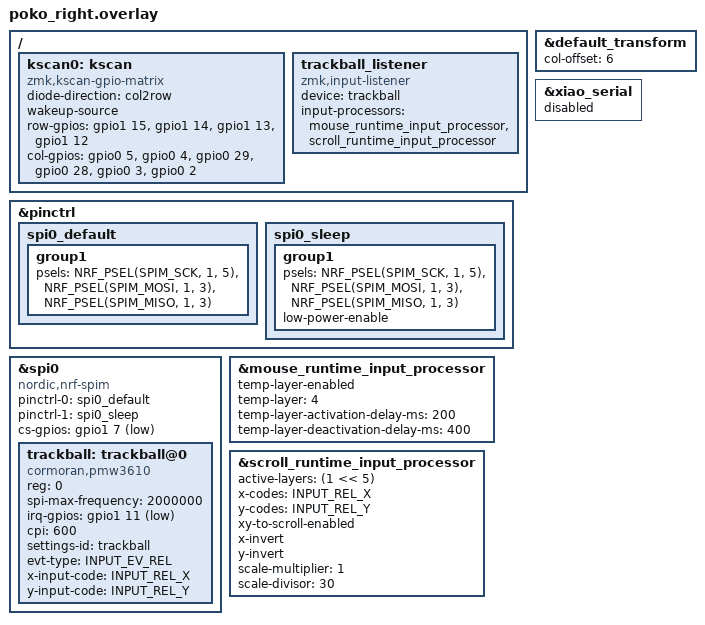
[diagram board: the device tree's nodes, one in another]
/*
 * poko 右手（セントラル・トラックボールあり）
 *
 * 右がセントラルなので zmk,input-split によるペリフェラル→セントラル転送は不要。
 * SPI + PMW3610 + input-listener をそのまま書く（実装ノート §7）。
 *
 * kscan は poko.dtsi の include より前に置く（poko.dtsi の chosen が &kscan0 を参照するため）。
 */

#include <zephyr/dt-bindings/gpio/gpio.h>

/ {
    /*
     * マトリクス 4行 × 6列（トラボ穴のぶん23キー）
     *
     * ⚠ いまは【試作基板】のピン割当（v0.1-proto と同一・左右共通）。
     *   本番基板 right.kicad_pcb の割当は下のコメントアウト側。戻すときは
     *   ピン番号だけでなく diode-direction と GPIO フラグも必ずセットで戻すこと。
     *
     * ダイオード向きは左と同じ。試作 = row2col / 本番 = col2row。
     * 欠番の SW19 = ROW3/COL0 → col-offset=6 で RC(3,6) ＝ トラックボール位置。
     */
    kscan0: kscan {
        compatible = "zmk,kscan-gpio-matrix";
        diode-direction = "col2row";
        wakeup-source;

        row-gpios
            = <&gpio1 15 (GPIO_ACTIVE_HIGH | GPIO_PULL_DOWN)>   // ROW0 = D10 / P1.15
            , <&gpio1 14 (GPIO_ACTIVE_HIGH | GPIO_PULL_DOWN)>   // ROW1 = D9  / P1.14
            , <&gpio1 13 (GPIO_ACTIVE_HIGH | GPIO_PULL_DOWN)>   // ROW2 = D8  / P1.13
            , <&gpio1 12 (GPIO_ACTIVE_HIGH | GPIO_PULL_DOWN)>   // ROW3 = D7  / P1.12
            ;
        col-gpios
            = <&gpio0  5 GPIO_ACTIVE_HIGH>   // COL0 = D5  / P0.05
            , <&gpio0  4 GPIO_ACTIVE_HIGH>   // COL1 = D4  / P0.04
            , <&gpio0 29 GPIO_ACTIVE_HIGH>   // COL2 = D3  / P0.29
            , <&gpio0 28 GPIO_ACTIVE_HIGH>   // COL3 = D2  / P0.28
            , <&gpio0  3 GPIO_ACTIVE_HIGH>   // COL4 = D1  / P0.03
            , <&gpio0  2 GPIO_ACTIVE_HIGH>   // COL5 = D0  / P0.02
            ;
    };
};

#include "poko.dtsi"
#include <input/processors.dtsi>
#include <input/processors/runtime-input-processor.dtsi>
#include <zephyr/dt-bindings/input/input-event-codes.h>

/* 右手の物理列0-5 を論理列6-11 へ */
&default_transform {
    col-offset = <6>;
};

/*
 * 3線 SPI: PMW3610 の SDIO は双方向1本なので MOSI/MISO を同じピンに割り当てる。
 *
 * ⚠ nRF52840 は SPIM0 と TWIM0 が周辺 ID を共有する。Zephyr の base xiao_ble.dts で
 *   &i2c0 が有効だとビルドが落ちるので、その場合は &spi0 → &spi3 に置換
 *   （SPIM3 は TWI と共有しない。pinctrl はどのピンにもルーティング可）。
 *
 * ⚠ いまは【試作基板】の配線:
 *     SCLK = P1.03 / SDIO = P1.05 / nCS = P1.07 / MOTION = P0.15
 *   本番基板 right.kicad_pcb は SCLK と SDIO が逆、MOTION も P1.11 (D6) に移動
 *   （コメントアウト側）。
 */
&pinctrl {
    spi0_default: spi0_default {
        group1 {
            psels = <NRF_PSEL(SPIM_SCK,  1, 5)>,   // SCLK = P1.05
                    <NRF_PSEL(SPIM_MOSI, 1, 3)>,   // SDIO = P1.03
                    <NRF_PSEL(SPIM_MISO, 1, 3)>;   //  〃   （同一ピン）
        };
    };

    spi0_sleep: spi0_sleep {
        group1 {
            psels = <NRF_PSEL(SPIM_SCK,  1, 5)>,
                    <NRF_PSEL(SPIM_MOSI, 1, 3)>,
                    <NRF_PSEL(SPIM_MISO, 1, 3)>;
            low-power-enable;
        };
    };
};

&spi0 {
    status = "okay";
    compatible = "nordic,nrf-spim";
    pinctrl-0 = <&spi0_default>;
    pinctrl-1 = <&spi0_sleep>;
    pinctrl-names = "default", "sleep";
    cs-gpios = <&gpio1 7 GPIO_ACTIVE_LOW>;   // nCS = P1.07

    trackball: trackball@0 {
        status = "okay";
        /* DYA Studio の Trackball タブ対応ドライバ（cormoran/zmk-driver-pmw3610-with-custom-studio-rpc）。
           west.yml・poko_right.conf と3点セット。 */
        compatible = "cormoran,pmw3610";
        reg = <0>;
        spi-max-frequency = <2000000>;   /* PMW3610 は 2MHz 上限 */

        /* MOTION = P1.11 (D6)。NRESET は R12(10k) で 3V3 プルアップ固定なので GPIO 不要 */
        irq-gpios = <&gpio1 11 (GPIO_ACTIVE_LOW | GPIO_PULL_UP)>;

        /* 初期値。DYA Studio から変更すると settings 側の値が優先される */
        cpi = <600>;   /* RMK 版 (keyboard.toml の cpi / POINTING_CPI) に揃える */

        /* DYA Studio 上の設定キー名（cpi@trackball など） */
        settings-id = "trackball";

        /* 軸の反転はこのドライバでは DT ではなく Kconfig（CONFIG_PMW3610_INVERT_X） */

        evt-type = <INPUT_EV_REL>;
        x-input-code = <INPUT_REL_X>;
        y-input-code = <INPUT_REL_Y>;
    };
};

&xiao_serial { status = "disabled"; };

/ {
    trackball_listener {
        compatible = "zmk,input-listener";
        device = <&trackball>;

        /*
         * DYA Studio の Trackball タブから調整できる runtime input processor を通す。
         * 並び順が大事: mouse（全レイヤ）→ scroll（SCROLL レイヤの間だけ XY をホイールへ）。
         * DT の値は初期値で、Studio で変更すると settings 側の値が優先される。
         */
        input-processors = <&mouse_runtime_input_processor &scroll_runtime_input_processor>;
    };
};

/*
 * QMK 版の set_auto_mouse_layer(_MOUSE) 相当。
 * ボールを動かすと MOUSE レイヤ(4)が一時的に有効、停止 400ms で解除。
 * （旧 &zip_temp_layer 4 400 の置き換え）
 *
 * temp-layer-activation-delay-ms は require-prior-idle-ms 相当。
 * 最後のキー押下からこの時間が経つまではボールが動いてもレイヤに乗らない
 * （タイピング中の誤爆防止。未指定だと 100ms）。
 * 右手がセントラルなので、左手のキー押下もちゃんと数えられる。
 */
&mouse_runtime_input_processor {
    temp-layer-enabled;
    temp-layer = <4>;
    temp-layer-activation-delay-ms = <200>;
    temp-layer-deactivation-delay-ms = <400>;
};

/*
 * QMK 版の poko_lptb_set_scroll_layer(_SCROLL) 相当。
 * SCROLL レイヤ(5)の間は XY をスクロールに読み替える。
 * x/y-invert は pointing_device_task_user() の v/h 反転（ナチュラルスクロール）に対応。
 * 処理順は XY→ホイール変換 → 反転 → スケールで、旧 zip_* 3段と同じ。
 *
 * 速さは RMK 版に揃える。RMK はスクロール中に CPI 200 ÷ divisor 10 = 20。
 * ZMK はレイヤで CPI を切り替えられないので、600 ÷ 30 = 20 で合わせる。
 */
&scroll_runtime_input_processor {
    active-layers = <(1 << 5)>;
    x-codes = <INPUT_REL_X>;
    y-codes = <INPUT_REL_Y>;
    xy-to-scroll-enabled;
    x-invert;
    y-invert;
    scale-multiplier = <1>;
    scale-divisor = <30>;
};
